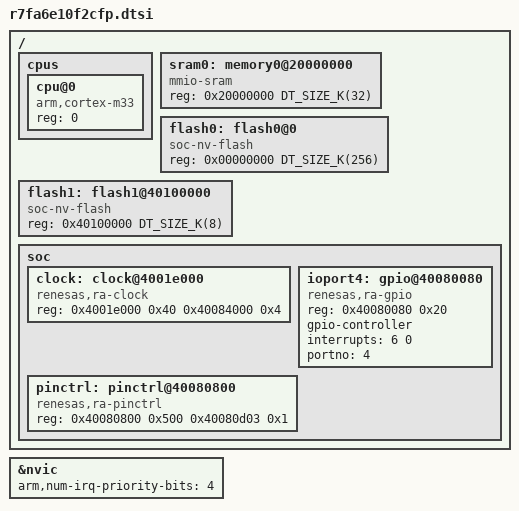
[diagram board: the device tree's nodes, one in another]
/*
 * Copyright (c) 2023 TOKITA Hiroshi <tokita.hiroshi@fujitsu.com>
 *
 * SPDX-License-Identifier: Apache-2.0
 */

#include <mem.h>
#include <freq.h>
#include <arm/armv8-m.dtsi>
#include <zephyr/dt-bindings/gpio/gpio.h>
#include <zephyr/dt-bindings/i2c/i2c.h>
#include <zephyr/dt-bindings/pwm/pwm.h>
#include <zephyr/dt-bindings/display/panel.h>

/ {
	cpus {
		#address-cells = <1>;
		#size-cells = <0>;

		cpu@0 {
			device_type = "cpu";
			compatible = "arm,cortex-m33";
			reg = <0>;
		};
	};

	sram0: memory0@20000000 {
		compatible = "mmio-sram";
		reg = <0x20000000 DT_SIZE_K(32)>;
	};

	flash0: flash0@0 {
		compatible = "soc-nv-flash";
		reg = <0x00000000 DT_SIZE_K(256)>;
	};

	flash1: flash1@40100000 {
		compatible = "soc-nv-flash";
		reg = <0x40100000 DT_SIZE_K(8)>;
	};

	soc {
		clock: clock@4001e000 {
			compatible = "renesas,ra-clock";
			reg = <0x4001e000 0x40 0x40084000 0x4>;
                        reg-names = "system", "mstp";
			#clock-cells = <0>;
		};

		ioport4: gpio@40080080 {
			compatible = "renesas,ra-gpio";
			reg = <0x40080080 0x20>;
			gpio-controller;
			#gpio-cells = <2>;
			interrupts = <6 0>;
			portno = <4>;
		};

		pinctrl: pinctrl@40080800 {
			compatible = "renesas,ra-pinctrl";
			reg = <0x40080800 0x500 0x40080d03 0x1>;
                        reg-names = "pfs", "pmisc_pwpr";
			status = "okay";
		};
	};
};

&nvic {
	arm,num-irq-priority-bits = <4>;
};
